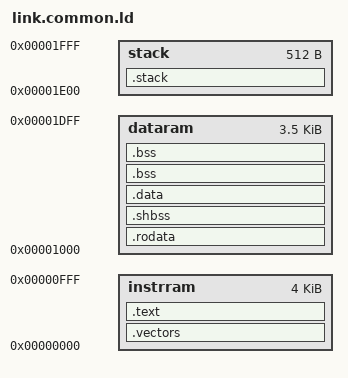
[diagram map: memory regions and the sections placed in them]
SEARCH_DIR(.)
__DYNAMIC  =  0;

MEMORY
{
    instrram    : ORIGIN = 0x00000000, LENGTH = 0x1000
    dataram     : ORIGIN = 0x00001000, LENGTH = 0x0E00
    stack       : ORIGIN = 0x00001E00, LENGTH = 0x0200
}

/* Stack information variables */
_min_stack      = 0x0200;   /* 4K - minimum stack space to reserve */
_stack_len     = LENGTH(stack);
_stack_start   = ORIGIN(stack) + LENGTH(stack);

SECTIONS
{
    .vectors :
    {
        . = ALIGN(4);
        KEEP(*(.vectors))
    } > instrram

    .text : {
        . = ALIGN(4);
        _stext = .;
        *(.text)
        _etext  =  .;
        *(.lit)
        *(.shdata)
        _endtext = .;
    }  > instrram
    /*--------------------------------------------------------------------*/
    /* Global constructor/destructor segement                             */
    /*--------------------------------------------------------------------*/
    .rodata : {
        . = ALIGN(4);
        *(.rodata);
        *(.rodata.*)
    } > dataram
    .shbss :
    {
        . = ALIGN(4);
        *(.shbss)
    } > dataram
    .data : {
        . = ALIGN(4);
        sdata  =  .;
        _sdata  =  .;
        *(.data);
        *(.data.*)
        edata  =  .;
        _edata  =  .;
    } > dataram
    .bss :
    {
        . = ALIGN(4);
        _bss_start = .;
        *(.bss)
        *(.bss.*)
        *(.sbss)
        *(.sbss.*)
        *(COMMON)
        _bss_end = .;
    } > dataram

    /* ensure there is enough room for stack */
    .stack (NOLOAD): {
        . = ALIGN(4);
        . = . + _min_stack ;
        . = ALIGN(4);
        stack = . ;
        _stack = . ;
    } > stack

    .stab  0 (NOLOAD) :
    {
        [ .stab ]
    }

    .stabstr  0 (NOLOAD) :
    {
        [ .stabstr ]
    }

    .bss :
    {
        . = ALIGN(4);
        _end = .;
    } > dataram
}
